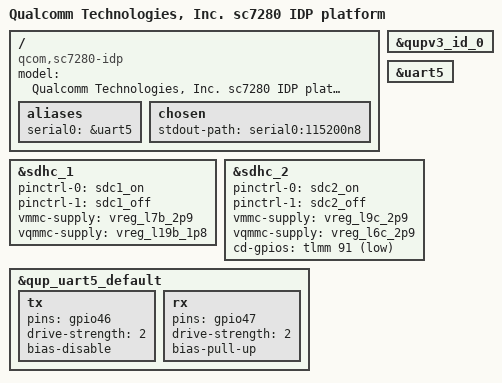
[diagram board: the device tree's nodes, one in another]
// SPDX-License-Identifier: BSD-3-Clause
/*
 * sc7280 IDP board device tree source
 *
 * Copyright (c) 2021, The Linux Foundation. All rights reserved.
 */

/dts-v1/;

#include "sc7280.dtsi"
#include <dt-bindings/gpio/gpio.h>

/ {
	model = "Qualcomm Technologies, Inc. sc7280 IDP platform";
	compatible = "qcom,sc7280-idp", "qcom,sc7280";

	aliases {
		serial0 = &uart5;
	};

	chosen {
		stdout-path = "serial0:115200n8";
	};
};

&qupv3_id_0 {
	status = "okay";
};

&uart5 {
	status = "okay";
};

&sdhc_1 {
	status = "okay";

	pinctrl-names = "default", "sleep";
	pinctrl-0 = <&sdc1_on>;
	pinctrl-1 = <&sdc1_off>;

	vmmc-supply = <&vreg_l7b_2p9>;
	vqmmc-supply = <&vreg_l19b_1p8>;
};

&sdhc_2 {
	status = "okay";

	pinctrl-names = "default","sleep";
	pinctrl-0 = <&sdc2_on>;
	pinctrl-1 = <&sdc2_off>;

	vmmc-supply = <&vreg_l9c_2p9>;
	vqmmc-supply = <&vreg_l6c_2p9>;

	cd-gpios = <&tlmm 91 GPIO_ACTIVE_LOW>;
};

/* PINCTRL - additions to nodes defined in sc7280.dtsi */

&qup_uart5_default {
	tx {
		pins = "gpio46";
		drive-strength = <2>;
		bias-disable;
	};

	rx {
		pins = "gpio47";
		drive-strength = <2>;
		bias-pull-up;
	};
};
